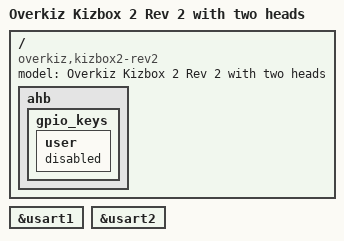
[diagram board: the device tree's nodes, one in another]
// SPDX-License-Identifier: GPL-2.0
/*
 * Copyright (C) 2017 Overkiz SAS
 *   Author: Kévin Raymond <k.raymond@overkiz.com>
 */
/dts-v1/;
#include "at91-kizbox2_common.dtsi"

/ {
	model = "Overkiz Kizbox 2 Rev 2 with two heads";
	compatible = "overkiz,kizbox2-rev2", "atmel,sama5d31", "atmel,sama5d3", "atmel,sama5";

	ahb {
		gpio_keys {
			user {
				status = "disabled";
			};
		};
	};
};

&usart1 {
	status = "okay";
};

&usart2 {
	status = "okay";
};

